# CPU_SYSTICK register map
Vendor: Texas Instruments
Peripheral module from a debugger description file (folder CC26x4).
Registers are 32-bit, access per field, reset 0x0 unless marked. A register's access mark holds for its fields unless they carry their own. Offsets are as the file gives them; lines under a group give offsets from that group; [hi:lo] are bit positions; {n}, {i} and the like mark numbered series; 'fields as' and 'values as' point back to an identical list; <NAME> marks a mode.

## CPU_SYSTICK — Cortex-M's System Timer (SYSTICK)
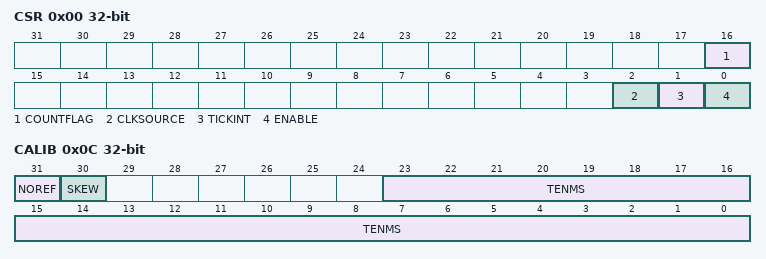
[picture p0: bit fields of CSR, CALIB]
0x00 CSR — Controls the SysTick timer and provides status data `FTSSS
  [16] COUNTFLAG rw — Indicates whether the counter has counted to zero since the last read of this register
  [2] CLKSOURCE rw — Indicates the SysTick clock source
  [1] TICKINT rw — Indicates whether counting to 0 causes the status of the SysTick exception to change to pending
  [0] ENABLE rw — Indicates the enabled status of the SysTick counter
0x04 RVR — Provides access SysTick timer counter reload value `FTSSS
  [23:0] RELOAD rw — The value to load into the SYST_CVR `FTSSS when the counter reaches 0
0x08 CVR — Reads or clears the SysTick timer current counter value `FTSSS
  [23:0] CURRENT wo — Writing any value clears the SysTick timer counter `FTSSS to zero
0x0C CALIB ro — Reads the SysTick timer calibration value and parameters `FTSSS
  [31] NOREF — Indicates whether the IMPLEMENTATION DEFINED reference clock is implemented
  [30] SKEW — Indicates whether the 10ms calibration value is exact
  [23:0] TENMS — Optionally, holds a reload value to be used for 10ms (100Hz) timing, subject to system clock skew errors. If this field is zero, the calibration value is not known
